VERSION ""

NS_ :

BS_:

BU_: ExtLogData2
VAL_TABLE_ Lane_conf 3 "very good lane conf" 2 "godd lane conf" 1 "bad lane conf" 0 "No lane conf" ;
VAL_TABLE_ LDW_availability 1 "available" 0 "unavalable" ;
VAL_TABLE_ Lane_type 6 "Invalid" 5 "Bott's Dots" 4 "Double Lane Mark" 3 "Road edge" 2 "None" 1 "Solid" 0 "Dashed" ;

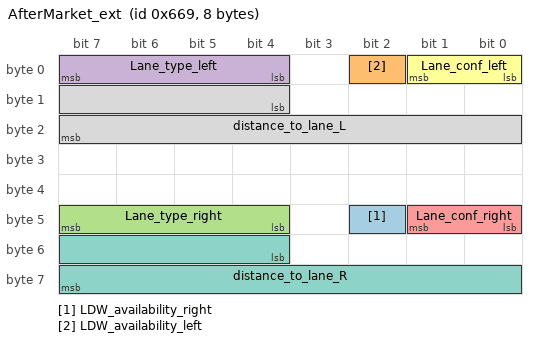
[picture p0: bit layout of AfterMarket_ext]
BO_ 1641 AfterMarket_ext: 8 Vector__XXX
 SG_ LDW_availability_right : 42|1@1- (1,0) [0|1] "" Vector__XXX
 SG_ LDW_availability_left : 2|1@1- (1,0) [0|1] "" Vector__XXX
 SG_ Lane_type_right : 44|4@1- (1,0) [0|6] "" Vector__XXX
 SG_ Lane_type_left : 4|4@1- (1,0) [0|6] "" Vector__XXX
 SG_ Lane_conf_right : 40|2@1- (1,0) [0|3] "" Vector__XXX
 SG_ Lane_conf_left : 0|2@1- (1,0) [0|3] "" Vector__XXX
 SG_ distance_to_lane_R : 52|12@1- (0.02,0) [-40|40] "meters" Vector__XXX
 SG_ distance_to_lane_L : 12|12@1- (0.02,0) [-40|40] "meters" Vector__XXX

BA_DEF_  "BusType" STRING ;
BA_DEF_DEF_  "BusType" "CAN";
VAL_ 1641 LDW_availability_right 1 "available" 0 "unavalable" ;
VAL_ 1641 LDW_availability_left 1 "available" 0 "unavalable" ;
VAL_ 1641 Lane_type_right 6 "Invalid" 5 "Bott's Dots" 4 "Double Lane Mark" 3 "Road edge" 2 "None" 1 "Solid" 0 "Dashed" ;
VAL_ 1641 Lane_type_left 6 "Invalid" 5 "Bott's Dots" 4 "Double Lane Mark" 3 "Road edge" 2 "None" 1 "Solid" 0 "Dashed" ;
VAL_ 1641 Lane_conf_right 3 "very good lane conf" 2 "godd lane conf" 1 "bad lane conf" 0 "No lane conf" ;
VAL_ 1641 Lane_conf_left 3 "very good lane conf" 2 "godd lane conf" 1 "bad lane conf" 0 "No lane conf" ;
